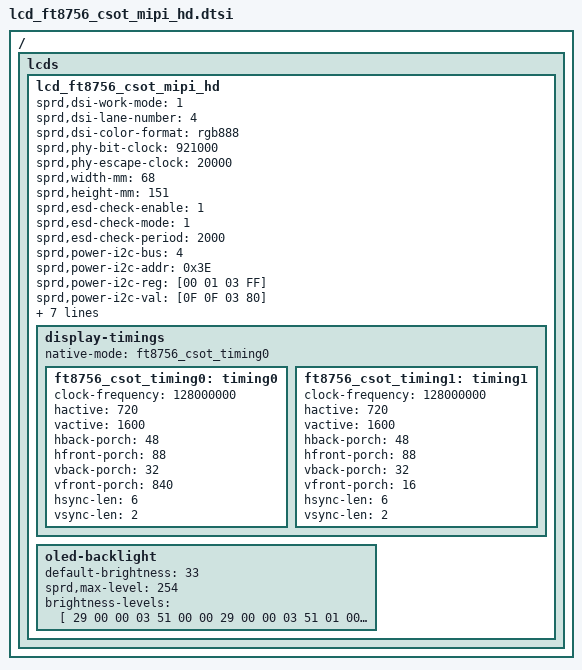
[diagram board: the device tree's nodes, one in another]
/*
 * ft8756 csot HD Scaling-Up LCD config dtsi file for spreadtrum
 *
 * Copyright (C) 2018, Spreadtrum Communications Inc.
 *
 * SPDX-License-Identifier: (GPL-2.0+ OR MIT)
 */

/ {
	fragment {
		target-path = "/";
		__overlay__ {
			lcds {
				lcd_ft8756_csot_mipi_hd: lcd_ft8756_csot_mipi_hd {

					sprd,dsi-work-mode = <1>; /* video burst mode*/
					sprd,dsi-lane-number = <4>;
					sprd,dsi-color-format = "rgb888";

					sprd,phy-bit-clock = <921000>;	/* kbps */
					sprd,phy-escape-clock = <20000>;/* kHz */

					sprd,width-mm = <68>;
					sprd,height-mm = <151>;

					sprd,esd-check-enable = <1>;
					sprd,esd-check-mode = <1>;
					sprd,esd-check-period = <2000>;
					//sprd,esd-check-register = <0xA>;
					//sprd,esd-check-value = <0x9c>;

					sprd,power-i2c-bus = <4>;
					sprd,power-i2c-addr = <0x3E>;
					/*sprd,power-i2c-speed = <400000>;*/
					sprd,power-i2c-reg = [00 01 03 FF];
					sprd,power-i2c-val = [0F 0F 03 80];

					sprd,reset-on-sequence = <1 10>, <0 10>, <1 35>;
					sprd,reset-off-sequence = <1 10>;

					//sprd,use-dcs-write;
					sprd,ft-type;

					sprd,initial-command = [
						29 00 00 02 00 00 
						29 00 00 04 FF 87 56 01 
						29 00 00 02 00 80 
						29 00 00 03 FF 87 56 
						29 00 00 02 00 A1 
						29 00 00 07 B3 02 D0 06 40 20 FC 
						29 00 00 02 00 80 
						29 00 00 07 C0 00 7E 00 10 00 22 
						29 00 00 02 00 90 
						29 00 00 07 C0 00 7E 00 10 00 22 
						29 00 00 02 00 A0 
						29 00 00 07 C0 01 17 00 10 00 22 
						29 00 00 02 00 B0 
						29 00 00 06 C0 00 7E 00 10 22 
						29 00 00 02 00 C1 
						29 00 00 09 C0 01 29 00 EA 00 C6 01 5F 
						29 00 00 02 00 D7 
						29 00 00 07 C0 00 C6 00 10 00 22 
						29 00 00 02 00 A3 
						29 00 00 07 C1 00 34 00 34 00 02 
						29 00 00 02 00 80 
						29 00 00 11 CE 01 81 09 13 00 9C 00 9C 00 60 00 65 00 90 00 98 
						29 00 00 02 00 90 
						29 00 00 10 CE 00 8E 0D CA 00 8E 80 09 13 00 04 00 19 1D 12 
						29 00 00 02 00 A0 
						29 00 00 04 CE 20 00 00 
						29 00 00 02 00 B0 
						29 00 00 04 CE 22 00 00 
						29 00 00 02 00 D1 
						29 00 00 08 CE 00 00 01 00 00 00 00 
						29 00 00 02 00 E1 
						29 00 00 0C CE 08 02 4D 02 4D 02 4D 00 00 00 00 
						29 00 00 02 00 F1 
						29 00 00 0A CE 15 0A 09 00 CA 01 68 01 71 
						29 00 00 02 00 B0 
						29 00 00 05 CF 00 00 89 8D 
						29 00 00 02 00 B5 
						29 00 00 05 CF 03 03 5A 5E 
						29 00 00 02 00 C0 
						29 00 00 05 CF 06 06 2C 30 
						29 00 00 02 00 C5 
						29 00 00 05 CF 00 00 08 0C 
						29 00 00 02 00 E8 
						29 00 00 02 C0 40 
						29 00 00 02 00 80 
						29 00 00 09 C2 84 00 07 83 83 00 07 83 
						29 00 00 02 00 A0 
						29 00 00 10 C2 82 04 00 07 83 81 04 00 07 83 00 04 00 07 83 
						29 00 00 02 00 B0 
						29 00 00 10 C2 01 04 00 07 83 02 04 00 07 83 03 04 00 07 83 
						29 00 00 02 00 C0 
						29 00 00 0B C2 04 04 00 07 83 05 04 00 07 83 
						29 00 00 02 00 E0 
						29 00 00 05 C2 77 77 77 77 
						29 00 00 02 00 C0 
						29 00 00 05 C3 99 99 99 99 
						29 00 00 02 00 80 
						29 00 00 11 CB 00 C5 00 00 05 05 00 05 0A 05 C5 00 05 05 00 C0 
						29 00 00 02 00 90 
						29 00 00 11 CB 00 00 00 00 00 00 00 00 00 00 00 00 00 00 00 00 
						29 00 00 02 00 A0 
						29 00 00 05 CB 00 00 00 00 
						29 00 00 02 00 B0 
						29 00 00 05 CB 10 51 94 50 
						29 00 00 02 00 C0 
						29 00 00 05 CB 10 51 94 50 
						29 00 00 02 00 80 
						29 00 00 11 CC 16 17 18 19 1A 1B 2D 25 25 2D 26 2D 00 29 03 2D 
						29 00 00 02 00 90 
						29 00 00 09 CC 07 09 0B 0D 2D 22 2D 24 
						29 00 00 02 00 80 
						29 00 00 11 CD 16 17 18 19 1A 1B 2D 25 25 2D 26 2D 00 29 02 2D 
						29 00 00 02 00 90 
						29 00 00 09 CD 06 08 0A 0C 2D 22 2D 24 
						29 00 00 02 00 A0 
						29 00 00 11 CC 16 17 18 19 1A 1B 2D 25 25 2D 26 2D 00 29 02 2D 
						29 00 00 02 00 B0 
						29 00 00 09 CC 08 06 0C 0A 2D 24 2D 23 
						29 00 00 02 00 A0 
						29 00 00 11 CD 16 17 18 19 1A 1B 2D 25 25 2D 26 2D 00 29 03 2D 
						29 00 00 02 00 B0 
						29 00 00 09 CD 09 07 0D 0B 2D 24 2D 23 
						29 00 00 02 00 80 
						29 00 00 02 A7 13 
						29 00 00 02 00 82 
						29 00 00 03 A7 22 02 
						29 00 00 02 00 85 
						29 00 00 02 C4 1C 
						29 00 00 02 00 A0 
						29 00 00 04 C4 8D D8 8D 
						29 00 00 02 00 93 
						29 00 00 02 C5 37 
						29 00 00 02 00 97 
						29 00 00 02 C5 37 
						29 00 00 02 00 B6 
						29 00 00 03 C5 2D 2D 
						29 00 00 02 00 97 
						29 00 00 02 C4 01 
						29 00 00 02 00 9B 
						29 00 00 02 F5 4B 
						29 00 00 02 00 93 
						29 00 00 03 F5 00 00 
						29 00 00 02 00 9D 
						29 00 00 02 F5 49 
						29 00 00 02 00 82 
						29 00 00 03 F5 00 00 
						29 00 00 02 00 8C 
						29 00 00 04 C3 00 00 00 
						29 00 00 02 00 84 
						29 00 00 03 C5 28 28 
						29 00 00 02 00 A4 
						29 00 00 02 D7 00 
						29 00 00 02 00 80 
						29 00 00 03 F5 59 59 
						29 00 00 02 00 84 
						29 00 00 04 F5 59 59 59 
						29 00 00 02 00 96 
						29 00 00 02 F5 59 
						29 00 00 02 00 A6 
						29 00 00 02 F5 59 
						29 00 00 02 00 CA 
						29 00 00 02 C0 80 
						29 00 00 02 00 B1 
						29 00 00 02 F5 1F 
						29 00 00 02 00 00 
						29 00 00 03 D8 2B 2B 
						29 00 00 02 00 00 
						29 00 00 03 D9 1E 1E 
						29 00 00 02 00 86 
						29 00 00 07 C0 01 04 01 01 10 03 
						29 00 00 02 00 96 
						29 00 00 07 C0 01 04 01 01 10 03 
						29 00 00 02 00 A6 
						29 00 00 07 C0 01 04 01 01 32 03 
						29 00 00 02 00 E9 
						29 00 00 07 C0 01 04 01 01 10 03 
						29 00 00 02 00 A3 
						29 00 00 07 CE 01 04 01 01 10 03 
						29 00 00 02 00 B3 
						29 00 00 07 CE 01 04 01 01 10 03 
						29 00 00 02 00 00 
						29 00 00 29 E1 05 06 09 10 5C 19 21 27 31 D5 39 3F 45 49 13 4E 56 5D 64 54 6A 71 78 81 EC 8A 90 96 9D 86 A6 B0 BE C8 3C D4 E6 F4 FF 1F 
						29 00 00 02 00 00 
						29 00 00 29 E2 05 06 09 10 5C 19 21 27 31 D5 39 3F 45 49 13 4E 56 5D 64 54 6A 71 78 81 EC 8A 90 96 9D 86 A6 B0 BE C8 3C D4 E6 F4 FF 1F 
						29 00 00 02 00 00 
						29 00 00 29 E3 05 06 09 10 5C 19 21 27 31 D5 39 3F 45 49 13 4E 56 5D 64 54 6A 71 78 81 EC 8A 90 96 9D 86 A6 B0 BE C8 3C D4 E6 F4 FF 1F 
						29 00 00 02 00 00 
						29 00 00 29 E4 05 06 09 10 5C 19 21 27 31 D5 39 3F 45 49 13 4E 56 5D 64 54 6A 71 78 81 EC 8A 90 96 9D 86 A6 B0 BE C8 3C D4 E6 F4 FF 1F 
						29 00 00 02 00 00 
						29 00 00 29 E5 05 06 09 10 5C 19 21 27 31 D5 39 3F 45 49 13 4E 56 5D 64 54 6A 71 78 81 EC 8A 90 96 9D 86 A6 B0 BE C8 3C D4 E6 F4 FF 1F 
						29 00 00 02 00 00 
						29 00 00 29 E6 05 06 09 10 5C 19 21 27 31 D5 39 3F 45 49 13 4E 56 5D 64 54 6A 71 78 81 EC 8A 90 96 9D 86 A6 B0 BE C8 3C D4 E6 F4 FF 1F 
						29 00 00 02 00 CC 
						29 00 00 02 C0 13 
						29 00 00 02 00 82 
						29 00 00 02 C5 3A 
						29 00 00 02 00 00 
						29 00 00 05 D2 08 02 56 93 
						29 00 00 02 00 80 
						29 00 00 0D CA CE BB AB 9F 96 8E 87 82 80 80 80 80 
						29 00 00 02 00 90 
						29 00 00 0A CA FD FF EA FC FF CC FA FF 66 

						29 00 00 02 00 00 
						29 00 00 04 FF 87 56 01 
						29 00 00 02 00 80 
						29 00 00 03 FF 87 56 
						29 00 00 02 00 B0 
						29 00 00 04 CA 00 00 0C 
						29 00 00 02 00 B5
						29 00 00 02 CA 03
						29 00 00 02 00 00 
						29 00 00 04 FF FF FF FF 

						13 00 00 02 35 00
						29 00 00 03 51 00 00
						29 00 00 02 53 2C
						29 00 00 02 55 01
						03 FA 00 01 11
						03 14 00 01 29
						];

					sprd,sleep-in-command = [
						03 32 00 01 28
						03 96 00 01 10
						29 00 00 02 00 00 
						29 00 00 04 FF 87 56 01 
						29 00 00 02 00 80 
						29 00 00 03 FF 87 56 
						29 00 00 02 00 00 
						29 96 00 05 F7 5A A5 95 27
						];

					display-timings {
						native-mode = <&ft8756_csot_timing0>;

						ft8756_csot_timing0: timing0 {
							clock-frequency = <128000000>;
							hactive = <720>;
							vactive = <1600>;
							hback-porch = <48>;
							hfront-porch = <88>;
							vback-porch = <32>;
							vfront-porch = <840>;
							hsync-len = <6>;
							vsync-len = <2>;
						};

						ft8756_csot_timing1: timing1 {
							clock-frequency = <128000000>;
							hactive = <720>;
							vactive = <1600>;
							hback-porch = <48>;
							hfront-porch = <88>;
							vback-porch = <32>;
							vfront-porch = <16>;
							hsync-len = <6>;
							vsync-len = <2>;
						};
					};

					oled-backlight {			
						default-brightness = <33>;	
						sprd,max-level = <254>;
						brightness-levels = [
            		    	29 00 00 03 51 00 00
							29 00 00 03 51 01 00
							29 00 00 03 51 02 00
							29 00 00 03 51 03 00
							29 00 00 03 51 04 00
							29 00 00 03 51 05 00
							29 00 00 03 51 06 00
							29 00 00 03 51 07 00
							29 00 00 03 51 08 00
							29 00 00 03 51 09 00
							29 00 00 03 51 0A 00
							29 00 00 03 51 0B 00
							29 00 00 03 51 0C 00
							29 00 00 03 51 0D 00
							29 00 00 03 51 0E 00
							29 00 00 03 51 0F 00
							29 00 00 03 51 10 00
							29 00 00 03 51 11 00
							29 00 00 03 51 12 00
							29 00 00 03 51 13 00
							29 00 00 03 51 14 00
							29 00 00 03 51 15 00
							29 00 00 03 51 16 00
							29 00 00 03 51 17 00
							29 00 00 03 51 18 00
							29 00 00 03 51 19 00
							29 00 00 03 51 1A 00
							29 00 00 03 51 1B 00
							29 00 00 03 51 1C 00
							29 00 00 03 51 1D 00
							29 00 00 03 51 1E 00
							29 00 00 03 51 1F 00
							29 00 00 03 51 20 00
							29 00 00 03 51 21 00
							29 00 00 03 51 22 00
							29 00 00 03 51 23 00
							29 00 00 03 51 24 00
							29 00 00 03 51 25 00
							29 00 00 03 51 26 00
							29 00 00 03 51 27 00
							29 00 00 03 51 28 00
							29 00 00 03 51 29 00
							29 00 00 03 51 2A 00
							29 00 00 03 51 2B 00
							29 00 00 03 51 2C 00
							29 00 00 03 51 2D 00
							29 00 00 03 51 2E 00
							29 00 00 03 51 2F 00
							29 00 00 03 51 30 00
							29 00 00 03 51 31 00
							29 00 00 03 51 32 00
							29 00 00 03 51 33 00
							29 00 00 03 51 34 00
							29 00 00 03 51 35 00
							29 00 00 03 51 36 00
							29 00 00 03 51 37 00
							29 00 00 03 51 38 00
							29 00 00 03 51 39 00
							29 00 00 03 51 3A 00
							29 00 00 03 51 3B 00
							29 00 00 03 51 3C 00
							29 00 00 03 51 3D 00
							29 00 00 03 51 3E 00
							29 00 00 03 51 3F 00
							29 00 00 03 51 40 00
							29 00 00 03 51 41 00
							29 00 00 03 51 42 00
							29 00 00 03 51 43 00
							29 00 00 03 51 44 00
							29 00 00 03 51 45 00
							29 00 00 03 51 46 00
							29 00 00 03 51 47 00
							29 00 00 03 51 48 00
							29 00 00 03 51 49 00
							29 00 00 03 51 4A 00
							29 00 00 03 51 4B 00
							29 00 00 03 51 4C 00
							29 00 00 03 51 4D 00
							29 00 00 03 51 4E 00
							29 00 00 03 51 4F 00
							29 00 00 03 51 50 00
							29 00 00 03 51 51 00
							29 00 00 03 51 52 00
							29 00 00 03 51 53 00
							29 00 00 03 51 54 00
							29 00 00 03 51 55 00
							29 00 00 03 51 56 00
							29 00 00 03 51 57 00
							29 00 00 03 51 58 00
							29 00 00 03 51 59 00
							29 00 00 03 51 5A 00
							29 00 00 03 51 5B 00
							29 00 00 03 51 5C 00
							29 00 00 03 51 5D 00
							29 00 00 03 51 5E 00
							29 00 00 03 51 5F 00
							29 00 00 03 51 60 00
							29 00 00 03 51 61 00
							29 00 00 03 51 62 00
							29 00 00 03 51 63 00
							29 00 00 03 51 64 00
							29 00 00 03 51 65 00
							29 00 00 03 51 66 00
							29 00 00 03 51 67 00
							29 00 00 03 51 68 00
							29 00 00 03 51 69 00
							29 00 00 03 51 6A 00
							29 00 00 03 51 6B 00
							29 00 00 03 51 6C 00
							29 00 00 03 51 6D 00
							29 00 00 03 51 6E 00
							29 00 00 03 51 6F 00
							29 00 00 03 51 70 00
							29 00 00 03 51 71 00
							29 00 00 03 51 72 00
							29 00 00 03 51 73 00
							29 00 00 03 51 74 00
							29 00 00 03 51 75 00
							29 00 00 03 51 76 00
							29 00 00 03 51 77 00
							29 00 00 03 51 78 00
							29 00 00 03 51 79 00
							29 00 00 03 51 7A 00
							29 00 00 03 51 7B 00
							29 00 00 03 51 7C 00
							29 00 00 03 51 7D 00
							29 00 00 03 51 7E 00
							29 00 00 03 51 7F 00
							29 00 00 03 51 80 00
							29 00 00 03 51 81 00
							29 00 00 03 51 82 00
							29 00 00 03 51 83 00
							29 00 00 03 51 84 00
							29 00 00 03 51 85 00
							29 00 00 03 51 86 00
							29 00 00 03 51 87 00
							29 00 00 03 51 88 00
							29 00 00 03 51 89 00
							29 00 00 03 51 8A 00
							29 00 00 03 51 8B 00
							29 00 00 03 51 8C 00
							29 00 00 03 51 8D 00
							29 00 00 03 51 8E 00
							29 00 00 03 51 8F 00
							29 00 00 03 51 90 00
							29 00 00 03 51 91 00
							29 00 00 03 51 92 00
							29 00 00 03 51 93 00
							29 00 00 03 51 94 00
							29 00 00 03 51 95 00
							29 00 00 03 51 96 00
							29 00 00 03 51 97 00
							29 00 00 03 51 98 00
							29 00 00 03 51 99 00
							29 00 00 03 51 9A 00
							29 00 00 03 51 9B 00
							29 00 00 03 51 9C 00
							29 00 00 03 51 9D 00
							29 00 00 03 51 9E 00
							29 00 00 03 51 9F 00
							29 00 00 03 51 A0 00
							29 00 00 03 51 A1 00
							29 00 00 03 51 A2 00
							29 00 00 03 51 A3 00
							29 00 00 03 51 A4 00
							29 00 00 03 51 A5 00
							29 00 00 03 51 A6 00
							29 00 00 03 51 A7 00
							29 00 00 03 51 A8 00
							29 00 00 03 51 A9 00
							29 00 00 03 51 AA 00
							29 00 00 03 51 AB 00
							29 00 00 03 51 AC 00
							29 00 00 03 51 AD 00
							29 00 00 03 51 AE 00
							29 00 00 03 51 AF 00
							29 00 00 03 51 B0 00
							29 00 00 03 51 B1 00
							29 00 00 03 51 B2 00
							29 00 00 03 51 B3 00
							29 00 00 03 51 B4 00
							29 00 00 03 51 B5 00
							29 00 00 03 51 B6 00
							29 00 00 03 51 B7 00
							29 00 00 03 51 B8 00
							29 00 00 03 51 B9 00
							29 00 00 03 51 BA 00
							29 00 00 03 51 BB 00
							29 00 00 03 51 BC 00
							29 00 00 03 51 BD 00
							29 00 00 03 51 BE 00
							29 00 00 03 51 BF 00
							29 00 00 03 51 C0 00
							29 00 00 03 51 C1 00
							29 00 00 03 51 C2 00
							29 00 00 03 51 C3 00
							29 00 00 03 51 C4 00
							29 00 00 03 51 C5 00
							29 00 00 03 51 C6 00
							29 00 00 03 51 C7 00
							29 00 00 03 51 C8 00
							29 00 00 03 51 C9 00
							29 00 00 03 51 CA 00
							29 00 00 03 51 CB 00
							29 00 00 03 51 CC 00
							29 00 00 03 51 CD 00
							29 00 00 03 51 CE 00
							29 00 00 03 51 CF 00
							29 00 00 03 51 D0 00
							29 00 00 03 51 D1 00
							29 00 00 03 51 D2 00
							29 00 00 03 51 D3 00
							29 00 00 03 51 D4 00
							29 00 00 03 51 D5 00
							29 00 00 03 51 D6 00
							29 00 00 03 51 D7 00
							29 00 00 03 51 D8 00
							29 00 00 03 51 D9 00
							29 00 00 03 51 DA 00
							29 00 00 03 51 DB 00
							29 00 00 03 51 DC 00
							29 00 00 03 51 DD 00
							29 00 00 03 51 DE 00
							29 00 00 03 51 DF 00
							29 00 00 03 51 E0 00
							29 00 00 03 51 E1 00
							29 00 00 03 51 E2 00
							29 00 00 03 51 E3 00
							29 00 00 03 51 E4 00
							29 00 00 03 51 E5 00
							29 00 00 03 51 E6 00
							29 00 00 03 51 E7 00
							29 00 00 03 51 E8 00
							29 00 00 03 51 E9 00
							29 00 00 03 51 EA 00
							29 00 00 03 51 EB 00
							29 00 00 03 51 EC 00
							29 00 00 03 51 ED 00
							29 00 00 03 51 EE 00
							29 00 00 03 51 EF 00
							29 00 00 03 51 F0 00
							29 00 00 03 51 F1 00
							29 00 00 03 51 F2 00
							29 00 00 03 51 F3 00
							29 00 00 03 51 F4 00
							29 00 00 03 51 F5 03
							29 00 00 03 51 F6 06
							29 00 00 03 51 F7 09
							29 00 00 03 51 F8 0C
							29 00 00 03 51 F9 0F
							29 00 00 03 51 FB 02
							29 00 00 03 51 FC 05
							29 00 00 03 51 FD 08
							29 00 00 03 51 FE 0B
							29 00 00 03 51 FF 0F
						];
					};
				};
			};
		};
	};
};
